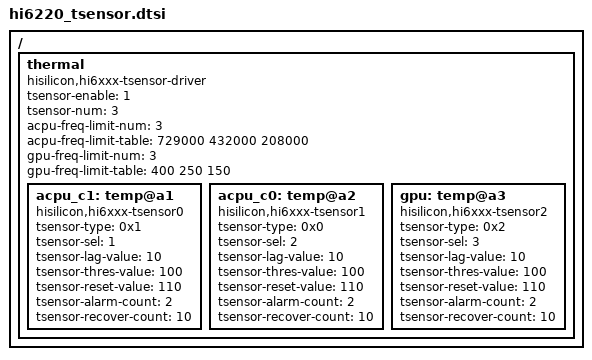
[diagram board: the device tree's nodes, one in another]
/{
    /*Tsensor温度保护驱动*/
	thermal {
		compatible = "hisilicon,hi6xxx-tsensor-driver";
		tsensor-enable = <1>;                            /*温度保护是否使能*/
		tsensor-num = <3>;                               /*Tsensor测点个数*/
		acpu-freq-limit-num = <3>;                       /*Acpu频率限制profile个数*/
		acpu-freq-limit-table = <729000 432000 208000>;  /*Acpu频率限制profile，KHz*/
		gpu-freq-limit-num = <3>;                        /*Gpu频率限制profile个数*/
		gpu-freq-limit-table = <400 250 150>;            /*Gpu频率限制profile，MHz*/
		
		acpu_c1: temp@a1 {
		    compatible = "hisilicon,hi6xxx-tsensor0";
		    tsensor-type   = <0x1>;                      /*该Tsensor测点类型，0对应ACPU_CLUSTER0, 1对应ACPU_CLUSTER1, 2对应GPU*/
			tsensor-sel    = <1>;                        /*该Tsensor类型对应IP中Select需填入的值*/
			tsensor-lag-value = <10>;                    /*该测点的滞回温度*/
			tsensor-thres-value = <100>;                 /*该测点的告警温度*/
			tsensor-reset-value = <110>;                 /*该测点的复位温度*/
			tsensor-alarm-count = <2>;                   /*该测点告警计数，计数达到该值才进行启动温度保护*/
			tsensor-recover-count = <10>;                /*该测试恢复计数，计数达到该值才进行取消温度保护*/
		};

		acpu_c0: temp@a2 {
		    compatible = "hisilicon,hi6xxx-tsensor1";
		    tsensor-type   = <0x0>;   /*acpu_c0:0; acpu_c1:1; gpu:2*/
			tsensor-sel    = <2>;     /*sensor select value*/
			tsensor-lag-value = <10>;
			tsensor-thres-value = <100>;  /*temperatur to send a warning irq*/
			tsensor-reset-value = <110>;  /*temperatur to reset soc*/
			tsensor-alarm-count = <2>;    /**/
			tsensor-recover-count = <10>; /**/
		};
		
		gpu: temp@a3 {
		    compatible = "hisilicon,hi6xxx-tsensor2";
		    tsensor-type   = <0x2>;   /*acpu_c0:0; acpu_c1:1; gpu:2*/
			tsensor-sel    = <3>;     /*sensor select value*/
			tsensor-lag-value = <10>;
			tsensor-thres-value = <100>;  /*temperatur to send a warning irq*/
			tsensor-reset-value = <110>;  /*temperatur to reset soc*/
			tsensor-alarm-count = <2>;    /**/
			tsensor-recover-count = <10>; /**/
		};
	};
};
